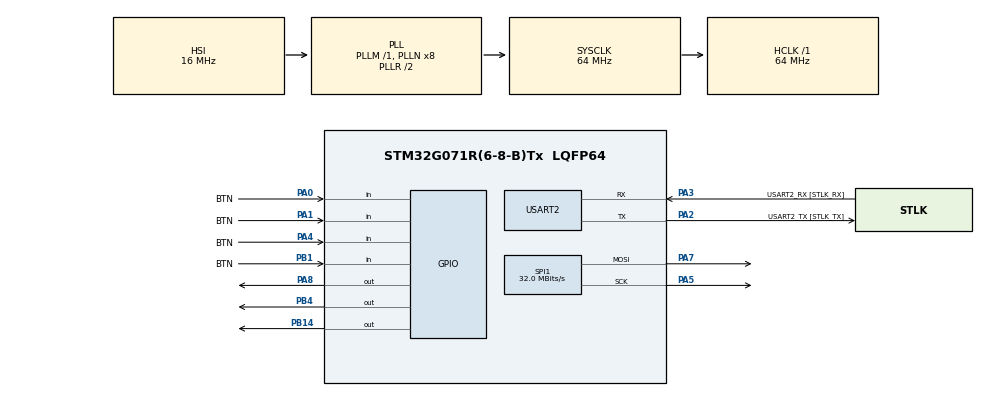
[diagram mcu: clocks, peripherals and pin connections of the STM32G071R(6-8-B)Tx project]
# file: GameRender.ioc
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Dma.Request0=SPI1_TX
Dma.SPI1_TX.0.Direction=DMA_MEMORY_TO_PERIPH
Dma.SPI1_TX.0.EventEnable=DISABLE
Dma.SPI1_TX.0.Instance=DMA1_Channel1
Dma.SPI1_TX.0.MemDataAlignment=DMA_MDATAALIGN_BYTE
Dma.SPI1_TX.0.MemInc=DMA_MINC_ENABLE
Dma.SPI1_TX.0.Mode=DMA_NORMAL
Dma.SPI1_TX.0.PeriphDataAlignment=DMA_PDATAALIGN_BYTE
Dma.SPI1_TX.0.PeriphInc=DMA_PINC_DISABLE
Dma.SPI1_TX.0.Polarity=HAL_DMAMUX_REQ_GEN_RISING
Dma.SPI1_TX.0.Priority=DMA_PRIORITY_LOW
Dma.SPI1_TX.0.RequestNumber=1
Dma.SPI1_TX.0.SignalID=NONE
Dma.SPI1_TX.0.SyncEnable=DISABLE
Dma.SPI1_TX.0.SyncPolarity=HAL_DMAMUX_SYNC_NO_EVENT
Dma.SPI1_TX.0.SyncRequestNumber=1
Dma.SPI1_TX.0.SyncSignalID=NONE
Mcu.Family=STM32G0
Mcu.Name=STM32G071R(6-8-B)Tx
Mcu.Package=LQFP64
NVIC.DMA1_Channel1_IRQn=true\:0\:0\:false\:false\:true\:false\:true\:true
PA0.GPIO_Label=BTN
PA0.GPIO_PuPd=GPIO_PULLUP
PA0.Signal=GPIO_Input
PA1.GPIO_Label=BTN
PA1.GPIO_PuPd=GPIO_PULLUP
PA1.Signal=GPIO_Input
PA13.GPIO_Label=TMS
PA13.Mode=Serial_Wire
PA13.Signal=SYS_SWDIO
PA14-BOOT0.GPIO_Label=TCK
PA14-BOOT0.Mode=Serial_Wire
PA14-BOOT0.Signal=SYS_SWCLK
PA2.GPIO_Label=USART2_TX [STLK_TX]
PA2.GPIO_PuPd=GPIO_PULLUP
PA2.Mode=Asynchronous
PA2.Signal=USART2_TX
PA3.GPIO_Label=USART2_RX [STLK_RX]
PA3.GPIO_PuPd=GPIO_PULLUP
PA3.Mode=Asynchronous
PA3.Signal=USART2_RX
PA4.GPIO_Label=BTN
PA4.GPIO_PuPd=GPIO_PULLUP
PA4.Signal=GPIO_Input
PA5.GPIO_Speed=GPIO_SPEED_FREQ_VERY_HIGH
PA5.Mode=TX_Only_Simplex_Unidirect_Master
PA5.Signal=SPI1_SCK
PA7.GPIO_Speed=GPIO_SPEED_FREQ_VERY_HIGH
PA7.Mode=TX_Only_Simplex_Unidirect_Master
PA7.Signal=SPI1_MOSI
PA8.Signal=GPIO_Output
PB1.GPIO_Label=BTN
PB1.GPIO_PuPd=GPIO_PULLUP
PB1.Signal=GPIO_Input
PB14.GPIO_Speed=GPIO_SPEED_FREQ_HIGH
PB14.PinState=GPIO_PIN_RESET
PB14.Signal=GPIO_Output
PB4.GPIO_Speed=GPIO_SPEED_FREQ_HIGH
PB4.PinState=GPIO_PIN_RESET
PB4.Signal=GPIO_Output
PC14-OSC32_IN\ (PC14).Signal=RCC_OSC32_IN
PC15-OSC32_OUT\ (PC15).Signal=RCC_OSC32_OUT
PF0-OSC_IN\ (PF0).GPIO_Label=MCO
PF0-OSC_IN\ (PF0).Mode=HSE-External-Oscillator
PF0-OSC_IN\ (PF0).Signal=RCC_OSC_IN
PF1-OSC_OUT\ (PF1).Mode=HSE-External-Oscillator
PF1-OSC_OUT\ (PF1).Signal=RCC_OSC_OUT
ProjectManager.HeapSize=0x200
ProjectManager.StackSize=0x400
ProjectManager.TargetToolchain=STM32CubeIDE
RCC.ADCFreq_Value=64000000
RCC.AHBFreq_Value=64000000
RCC.CortexFreq_Value=64000000
RCC.EXTERNAL_CLOCK_VALUE=12288000
RCC.HCLKFreq_Value=64000000
RCC.HSE_VALUE=8000000
RCC.HSI_VALUE=16000000
RCC.LSE_VALUE=32768
RCC.SYSCLKFreq_VALUE=64000000
RCC.SYSCLKSource=RCC_SYSCLKSOURCE_PLLCLK
RCC.VCOOutputFreq_Value=128000000
SPI1.BaudRatePrescaler=SPI_BAUDRATEPRESCALER_2
SPI1.CalculateBaudRate=32.0 MBits/s
SPI1.DataSize=SPI_DATASIZE_8BIT
SPI1.Direction=SPI_DIRECTION_2LINES
SPI1.Mode=SPI_MODE_MASTER
SPI1.VirtualType=VM_MASTER
USART2.VirtualMode-Asynchronous=VM_ASYNC
board=NUCLEO-G071RB

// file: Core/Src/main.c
/* USER CODE BEGIN Header */
/**
  ******************************************************************************
  * @file           : main.c
  * @brief          : Main program body
  ******************************************************************************
  * @attention
  *
  * Copyright (c) 2025 STMicroelectronics.
  * All rights reserved.
  *
  * This software is licensed under terms that can be found in the LICENSE file
  * in the root directory of this software component.
  * If no LICENSE file comes with this software, it is provided AS-IS.
  *
  ******************************************************************************
  */
/* USER CODE END Header */
#include "main.h"

/* USER CODE BEGIN Includes */
#include "stm32g0xx_hal.h"
#include "ILI9341_STM32_Driver.h"
#include "EngineH/engine.h"
#include "EngineH/input.h"
#include "EngineH/engine_api.h"
#include "fonts.h"
/* USER CODE END Includes */

SPI_HandleTypeDef hspi1;
DMA_HandleTypeDef hdma_spi1_tx;

UART_HandleTypeDef huart2;

void SystemClock_Config(void);
static void MX_GPIO_Init(void);
static void MX_DMA_Init(void);
static void MX_USART2_UART_Init(void);
static void MX_SPI1_Init(void);

int main(void)
{

  /* MCU Configuration--------------------------------------------------------*/

  /* Reset of all peripherals, Initializes the Flash interface and the Systick. */
  HAL_Init();

  /* Configure the system clock */
  SystemClock_Config();

  /* Initialize all configured peripherals */
  MX_GPIO_Init();
  MX_DMA_Init();
  MX_USART2_UART_Init();
  MX_SPI1_Init();
  /* USER CODE BEGIN 2 */
  /* init tft first (driver in project) */
  ILI9341_Init();
  ILI9341_SetRotation(SCREEN_HORIZONTAL_2);
     /* Configure engine ticks (opţional) */
     Engine_SetLogicTick(40);  /* 25 Hz logic */
     Engine_SetRenderTick(25); /* 40 ms -> 25 Hz render */

     /* Init engine (will call Start()) and start runloop */
     Engine_Init();
     Engine_RunLoop();

  /* USER CODE END 2 */

  /* Infinite loop */
  while (1)
  {

  }
}

void SystemClock_Config(void)
{
  RCC_OscInitTypeDef RCC_OscInitStruct = {0};
  RCC_ClkInitTypeDef RCC_ClkInitStruct = {0};

  /** Configure the main internal regulator output voltage
  */
  HAL_PWREx_ControlVoltageScaling(PWR_REGULATOR_VOLTAGE_SCALE1);

  /** Initializes the RCC Oscillators according to the specified parameters
  * in the RCC_OscInitTypeDef structure.
  */
  RCC_OscInitStruct.OscillatorType = RCC_OSCILLATORTYPE_HSI;
  RCC_OscInitStruct.HSIState = RCC_HSI_ON;
  RCC_OscInitStruct.HSIDiv = RCC_HSI_DIV1;
  RCC_OscInitStruct.HSICalibrationValue = RCC_HSICALIBRATION_DEFAULT;
  RCC_OscInitStruct.PLL.PLLState = RCC_PLL_ON;
  RCC_OscInitStruct.PLL.PLLSource = RCC_PLLSOURCE_HSI;
  RCC_OscInitStruct.PLL.PLLM = RCC_PLLM_DIV1;
  RCC_OscInitStruct.PLL.PLLN = 8;
  RCC_OscInitStruct.PLL.PLLP = RCC_PLLP_DIV2;
  RCC_OscInitStruct.PLL.PLLQ = RCC_PLLQ_DIV2;
  RCC_OscInitStruct.PLL.PLLR = RCC_PLLR_DIV2;
  if (HAL_RCC_OscConfig(&RCC_OscInitStruct) != HAL_OK)
  {
    Error_Handler();
  }

  /** Initializes the CPU, AHB and APB buses clocks
  */
  RCC_ClkInitStruct.ClockType = RCC_CLOCKTYPE_HCLK|RCC_CLOCKTYPE_SYSCLK
                              |RCC_CLOCKTYPE_PCLK1;
  RCC_ClkInitStruct.SYSCLKSource = RCC_SYSCLKSOURCE_PLLCLK;
  RCC_ClkInitStruct.AHBCLKDivider = RCC_SYSCLK_DIV1;
  RCC_ClkInitStruct.APB1CLKDivider = RCC_HCLK_DIV1;

  if (HAL_RCC_ClockConfig(&RCC_ClkInitStruct, FLASH_LATENCY_2) != HAL_OK)
  {
    Error_Handler();
  }
}

static void MX_SPI1_Init(void)
{

  /* SPI1 parameter configuration*/
  hspi1.Instance = SPI1;
  hspi1.Init.Mode = SPI_MODE_MASTER;
  hspi1.Init.Direction = SPI_DIRECTION_2LINES;
  hspi1.Init.DataSize = SPI_DATASIZE_8BIT;
  hspi1.Init.CLKPolarity = SPI_POLARITY_LOW;
  hspi1.Init.CLKPhase = SPI_PHASE_1EDGE;
  hspi1.Init.NSS = SPI_NSS_SOFT;
  hspi1.Init.BaudRatePrescaler = SPI_BAUDRATEPRESCALER_2;
  hspi1.Init.FirstBit = SPI_FIRSTBIT_MSB;
  hspi1.Init.TIMode = SPI_TIMODE_DISABLE;
  hspi1.Init.CRCCalculation = SPI_CRCCALCULATION_DISABLE;
  hspi1.Init.CRCPolynomial = 7;
  hspi1.Init.CRCLength = SPI_CRC_LENGTH_DATASIZE;
  hspi1.Init.NSSPMode = SPI_NSS_PULSE_ENABLE;
  if (HAL_SPI_Init(&hspi1) != HAL_OK)
  {
    Error_Handler();
  }

}

static void MX_USART2_UART_Init(void)
{

  huart2.Instance = USART2;
  huart2.Init.BaudRate = 115200;
  huart2.Init.WordLength = UART_WORDLENGTH_8B;
  huart2.Init.StopBits = UART_STOPBITS_1;
  huart2.Init.Parity = UART_PARITY_NONE;
  huart2.Init.Mode = UART_MODE_TX_RX;
  huart2.Init.HwFlowCtl = UART_HWCONTROL_NONE;
  huart2.Init.OverSampling = UART_OVERSAMPLING_16;
  huart2.Init.OneBitSampling = UART_ONE_BIT_SAMPLE_DISABLE;
  huart2.Init.ClockPrescaler = UART_PRESCALER_DIV1;
  huart2.AdvancedInit.AdvFeatureInit = UART_ADVFEATURE_NO_INIT;
  if (HAL_UART_Init(&huart2) != HAL_OK)
  {
    Error_Handler();
  }
  if (HAL_UARTEx_SetTxFifoThreshold(&huart2, UART_TXFIFO_THRESHOLD_1_8) != HAL_OK)
  {
    Error_Handler();
  }
  if (HAL_UARTEx_SetRxFifoThreshold(&huart2, UART_RXFIFO_THRESHOLD_1_8) != HAL_OK)
  {
    Error_Handler();
  }
  if (HAL_UARTEx_DisableFifoMode(&huart2) != HAL_OK)
  {
    Error_Handler();
  }

}

static void MX_DMA_Init(void)
{

  /* DMA controller clock enable */
  __HAL_RCC_DMA1_CLK_ENABLE();

  /* DMA interrupt init */
  /* DMA1_Channel1_IRQn interrupt configuration */
  HAL_NVIC_SetPriority(DMA1_Channel1_IRQn, 0, 0);
  HAL_NVIC_EnableIRQ(DMA1_Channel1_IRQn);

}

static void MX_GPIO_Init(void)
{
  GPIO_InitTypeDef GPIO_InitStruct = {0};

  /* GPIO Ports Clock Enable */
  __HAL_RCC_GPIOC_CLK_ENABLE();
  __HAL_RCC_GPIOF_CLK_ENABLE();
  __HAL_RCC_GPIOA_CLK_ENABLE();
  __HAL_RCC_GPIOB_CLK_ENABLE();

  /*Configure GPIO pin Output Level */
  HAL_GPIO_WritePin(GPIOB, GPIO_PIN_14|GPIO_PIN_4, GPIO_PIN_RESET);

  /*Configure GPIO pin Output Level */
  HAL_GPIO_WritePin(GPIOA, GPIO_PIN_8, GPIO_PIN_RESET);

  /*Configure GPIO pins : BTN_Pin BTNA1_Pin BTNA4_Pin */
  GPIO_InitStruct.Pin = BTN_Pin|BTNA1_Pin|BTNA4_Pin;
  GPIO_InitStruct.Mode = GPIO_MODE_INPUT;
  GPIO_InitStruct.Pull = GPIO_PULLUP;
  HAL_GPIO_Init(GPIOA, &GPIO_InitStruct);

  /*Configure GPIO pin : BTNB1_Pin */
  GPIO_InitStruct.Pin = BTNB1_Pin;
  GPIO_InitStruct.Mode = GPIO_MODE_INPUT;
  GPIO_InitStruct.Pull = GPIO_PULLUP;
  HAL_GPIO_Init(BTNB1_GPIO_Port, &GPIO_InitStruct);

  /*Configure GPIO pins : PB14 PB4 */
  GPIO_InitStruct.Pin = GPIO_PIN_14|GPIO_PIN_4;
  GPIO_InitStruct.Mode = GPIO_MODE_OUTPUT_PP;
  GPIO_InitStruct.Pull = GPIO_NOPULL;
  GPIO_InitStruct.Speed = GPIO_SPEED_FREQ_HIGH;
  HAL_GPIO_Init(GPIOB, &GPIO_InitStruct);

  /*Configure GPIO pin : PA8 */
  GPIO_InitStruct.Pin = GPIO_PIN_8;
  GPIO_InitStruct.Mode = GPIO_MODE_OUTPUT_PP;
  GPIO_InitStruct.Pull = GPIO_NOPULL;
  GPIO_InitStruct.Speed = GPIO_SPEED_FREQ_LOW;
  HAL_GPIO_Init(GPIOA, &GPIO_InitStruct);

}

void Error_Handler(void)
{
  __disable_irq();
  while (1)
  {
  }
}
